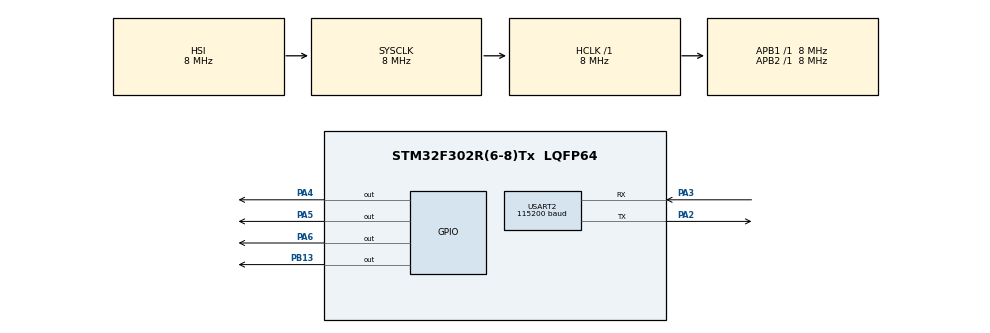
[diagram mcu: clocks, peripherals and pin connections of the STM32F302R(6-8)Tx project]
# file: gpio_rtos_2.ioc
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FREERTOS.Tasks01=ledTask,24,128,StartDefaultTask,Default,NULL,Dynamic,NULL,NULL
FREERTOS.configUSE_NEWLIB_REENTRANT=1
Mcu.Family=STM32F3
Mcu.Name=STM32F302R(6-8)Tx
Mcu.Package=LQFP64
NVIC.PriorityGroup=NVIC_PRIORITYGROUP_4
NVIC.TIM1_UP_TIM16_IRQn=true\:15\:0\:false\:false\:true\:false\:false\:true\:true
NVIC.TimeBase=TIM1_UP_TIM16_IRQn
NVIC.TimeBaseIP=TIM1
PA2.Mode=Asynchronous
PA2.Signal=USART2_TX
PA3.Mode=Asynchronous
PA3.Signal=USART2_RX
PA4.Signal=GPIO_Output
PA5.Signal=GPIO_Output
PA6.Signal=GPIO_Output
PB13.Signal=GPIO_Output
ProjectManager.HeapSize=0x200
ProjectManager.StackSize=0x400
ProjectManager.TargetToolchain=STM32CubeIDE
RCC.AHBFreq_Value=8000000
RCC.APB1Freq_Value=8000000
RCC.APB2Freq_Value=8000000
RCC.CortexFreq_Value=8000000
RCC.HSE_VALUE=8000000
RCC.HSI_VALUE=8000000
RCC.LSE_VALUE=32768
RCC.SYSCLKFreq_VALUE=8000000
USART2.BaudRate=115200
USART2.VirtualMode-Asynchronous=VM_ASYNC
USART2.WordLength=WORDLENGTH_7B
VP_FREERTOS_VS_CMSIS_V2.Mode=CMSIS_V2
VP_SYS_VS_tim1.Mode=TIM1
board=custom

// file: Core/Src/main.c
/* USER CODE BEGIN Header */
/**
  ******************************************************************************
  * @file           : main.c
  * @brief          : Main program body
  ******************************************************************************
  * @attention
  *
  * Copyright (c) 2024 STMicroelectronics.
  * All rights reserved.
  *
  * This software is licensed under terms that can be found in the LICENSE file
  * in the root directory of this software component.
  * If no LICENSE file comes with this software, it is provided AS-IS.
  *
  ******************************************************************************
  */
/* USER CODE END Header */
#include "main.h"
#include "cmsis_os.h"
#include <stdio.h>

UART_HandleTypeDef huart2;

/* Definitions for ledTask */
osThreadId_t ledTaskHandle;
const osThreadAttr_t ledTask_attributes = {
  .name = "ledTask",
  .stack_size = 128 * 4,
  .priority = (osPriority_t) osPriorityNormal,
};

void SystemClock_Config(void);
static void MX_GPIO_Init(void);
static void MX_USART2_UART_Init(void);
void StartDefaultTask(void *argument);
void StartLedTask(void *argument);

int main(void)
{

  /* MCU Configuration--------------------------------------------------------*/

  /* Reset of all peripherals, Initializes the Flash interface and the Systick. */
  HAL_Init();

  /* Configure the system clock */
  SystemClock_Config();

  /* Initialize all configured peripherals */
  MX_GPIO_Init();
  MX_USART2_UART_Init();

  /* Init scheduler */
  osKernelInitialize();

  /* Create the thread(s) */
  /* creation of ledTask */
  ledTaskHandle = osThreadNew(StartLedTask, NULL, &ledTask_attributes);

  /* Start scheduler */
  osKernelStart();

  /* We should never get here as control is now taken by the scheduler */

  /* Infinite loop */
  while (1)
  {

  }
}

void SystemClock_Config(void)
{
  RCC_OscInitTypeDef RCC_OscInitStruct = {0};
  RCC_ClkInitTypeDef RCC_ClkInitStruct = {0};

  /** Initializes the RCC Oscillators according to the specified parameters
  * in the RCC_OscInitTypeDef structure.
  */
  RCC_OscInitStruct.OscillatorType = RCC_OSCILLATORTYPE_HSI;
  RCC_OscInitStruct.HSIState = RCC_HSI_ON;
  RCC_OscInitStruct.HSICalibrationValue = RCC_HSICALIBRATION_DEFAULT;
  RCC_OscInitStruct.PLL.PLLState = RCC_PLL_NONE;
  if (HAL_RCC_OscConfig(&RCC_OscInitStruct) != HAL_OK)
  {
    Error_Handler();
  }

  /** Initializes the CPU, AHB and APB buses clocks
  */
  RCC_ClkInitStruct.ClockType = RCC_CLOCKTYPE_HCLK|RCC_CLOCKTYPE_SYSCLK
                              |RCC_CLOCKTYPE_PCLK1|RCC_CLOCKTYPE_PCLK2;
  RCC_ClkInitStruct.SYSCLKSource = RCC_SYSCLKSOURCE_HSI;
  RCC_ClkInitStruct.AHBCLKDivider = RCC_SYSCLK_DIV1;
  RCC_ClkInitStruct.APB1CLKDivider = RCC_HCLK_DIV1;
  RCC_ClkInitStruct.APB2CLKDivider = RCC_HCLK_DIV1;

  if (HAL_RCC_ClockConfig(&RCC_ClkInitStruct, FLASH_LATENCY_0) != HAL_OK)
  {
    Error_Handler();
  }
}

static void MX_USART2_UART_Init(void)
{

  huart2.Instance = USART2;
  huart2.Init.BaudRate = 115200;
  huart2.Init.StopBits = UART_STOPBITS_1;
  huart2.Init.Parity = UART_PARITY_NONE;
  huart2.Init.Mode = UART_MODE_TX_RX;
  huart2.Init.HwFlowCtl = UART_HWCONTROL_NONE;
  huart2.Init.OverSampling = UART_OVERSAMPLING_16;
  huart2.Init.OneBitSampling = UART_ONE_BIT_SAMPLE_DISABLE;
  huart2.AdvancedInit.AdvFeatureInit = UART_ADVFEATURE_NO_INIT;
  if (HAL_UART_Init(&huart2) != HAL_OK)
  {
    Error_Handler();
  }

}

static void MX_GPIO_Init(void)
{
  GPIO_InitTypeDef GPIO_InitStruct = {0};

  /* GPIO Ports Clock Enable */
  __HAL_RCC_GPIOA_CLK_ENABLE();
  __HAL_RCC_GPIOB_CLK_ENABLE();

  /*Configure GPIO pin Output Level */
  HAL_GPIO_WritePin(GPIOA, GPIO_PIN_4|GPIO_PIN_5|GPIO_PIN_6, GPIO_PIN_RESET);

  /*Configure GPIO pin Output Level */
  HAL_GPIO_WritePin(GPIOB, GPIO_PIN_13, GPIO_PIN_RESET);

  /*Configure GPIO pins : PA4 PA5 PA6 */
  GPIO_InitStruct.Pin = GPIO_PIN_4|GPIO_PIN_5|GPIO_PIN_6;
  GPIO_InitStruct.Mode = GPIO_MODE_OUTPUT_PP;
  GPIO_InitStruct.Pull = GPIO_NOPULL;
  GPIO_InitStruct.Speed = GPIO_SPEED_FREQ_LOW;
  HAL_GPIO_Init(GPIOA, &GPIO_InitStruct);

  /*Configure GPIO pin : PB13 */
  GPIO_InitStruct.Pin = GPIO_PIN_13;
  GPIO_InitStruct.Mode = GPIO_MODE_OUTPUT_PP;
  GPIO_InitStruct.Pull = GPIO_NOPULL;
  GPIO_InitStruct.Speed = GPIO_SPEED_FREQ_LOW;
  HAL_GPIO_Init(GPIOB, &GPIO_InitStruct);

}

void StartLedTask(void *argument)
{
  /* USER CODE BEGIN 5 */
  /* Infinite loop */
  for(;;)
  {
	HAL_GPIO_TogglePin(GPIOB, 13);
	HAL_GPIO_TogglePin(GPIOA, 4|5);
    uint32_t currentTimeTicks = osKernelGetTickCount();
    uint32_t tickFrequency = osKernelGetTickFreq(); // získání frekvence ticků
    uint32_t seconds = currentTimeTicks / tickFrequency;
    uint32_t milliseconds = (currentTimeTicks % tickFrequency) * 1000 / tickFrequency;

    char buffer[50];
    int len = snprintf(buffer, sizeof(buffer), "LED Toggled at time: %lu s %lu ms\r\n", seconds, milliseconds);
    HAL_UART_Transmit(&huart2, (uint8_t *)buffer, len, HAL_MAX_DELAY);

    osDelay(1000);
  }
  /* USER CODE END 5 */
}

void HAL_TIM_PeriodElapsedCallback(TIM_HandleTypeDef *htim)
{
  if (htim->Instance == TIM1) {
    HAL_IncTick();
  }
}

void Error_Handler(void)
{
  __disable_irq();
  while (1)
  {
  }
}
